# STM32L162ZET6 register map
File version: 1.0
Registers are 32-bit, access not given, reset 0x0 unless marked. A register's access mark holds for its fields unless they carry their own. Offsets are from the block's base; [hi:lo] are bit positions; {n}, {i} and the like mark numbered series.

## COMP
Base 0x40007C00
Same registers: COMP1 0x40007C00, COMP12_COMMON 0x40007C00, COMP2 0x40007C01
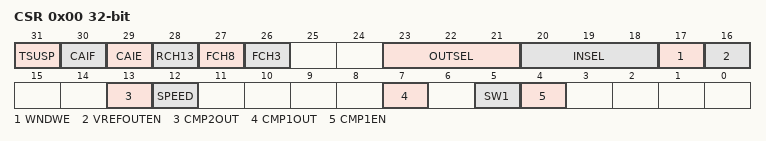
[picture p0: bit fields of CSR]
0x00 CSR
  [31] TSUSP, [30] CAIF, [29] CAIE, [28] RCH13, [27] FCH8, [26] FCH3, [23:21] OUTSEL, [20:18] INSEL, [17] WNDWE, [16] VREFOUTEN, [13] CMP2OUT, [12] SPEED, [7] CMP1OUT, [5] SW1, [4] CMP1EN

## RI
Base 0x40007C04
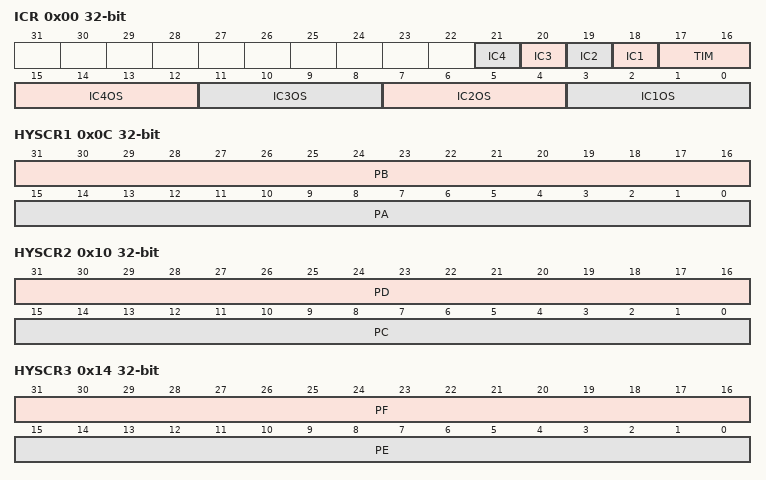
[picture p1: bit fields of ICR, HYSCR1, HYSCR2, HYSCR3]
0x00 ICR
  [n+17] IC{n} (n=1..4), [17:16] TIM, [4n-1:4n-4] IC{n}OS (n=1..4)
0x04 ASCR1
  [31] SCM, [26] VCOMP, [30:0] CH
0x08 ASCR2
  [n+14] CH{n}b (n=6..12), [n+16] CH{n}b (n=0..3), [28:4] GR6
0x0C HYSCR1
  [31:16] PB, [15:0] PA
0x10 HYSCR2
  [31:16] PD, [15:0] PC
0x14 HYSCR3
  [31:16] PF, [15:0] PE
0x18 HYSCR4
  [15:0] PG
0x1C ASMR1
  [15:0] PA
0x20 CMR1
  [15:0] PA
0x24 CICR1
  [15:0] PA
0x28 ASMR2
  [15:0] PB
0x2C CMR2
  [15:0] PB
0x30 CICR2
  [15:0] PB
0x34 ASMR3
  [15:0] PC
0x38 CMR3
  [15:0] PC
0x3C CICR3
  [15:0] PC
0x40 ASMR4
  [15:0] PF
0x44 CMR4
  [15:0] PF
0x48 CICR4
  [15:0] PF
0x4C ASMR5
  [15:0] PG
0x50 CMR5
  [15:0] PG
0x54 CICR5
  [15:0] PG

## OPAMP
Base 0x40007C5C
Same registers: OPAMP1 0x40007C5C, OPAMP2 0x40007C5D
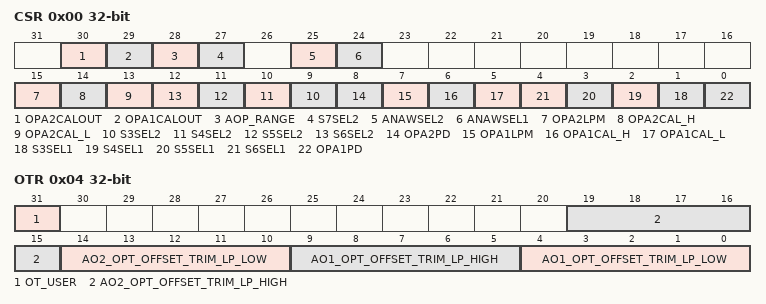
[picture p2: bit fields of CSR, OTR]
0x00 CSR
  [30] OPA2CALOUT, [29] OPA1CALOUT, [28] AOP_RANGE, [27] S7SEL2, [25] ANAWSEL2, [24] ANAWSEL1, [15] OPA2LPM, [14] OPA2CAL_H, [13] OPA2CAL_L, [n+6] S{n}SEL2 (n=3..6), [8] OPA2PD, [7] OPA1LPM, [6] OPA1CAL_H, [5] OPA1CAL_L, [n-2] S{n}SEL1 (n=3..6), [0] OPA1PD
0x04 OTR
  [31] OT_USER, [19:15] AO2_OPT_OFFSET_TRIM_LP_HIGH, [14:10] AO2_OPT_OFFSET_TRIM_LP_LOW, [9:5] AO1_OPT_OFFSET_TRIM_LP_HIGH, [4:0] AO1_OPT_OFFSET_TRIM_LP_LOW
0x08 LPOTR

## OPAMP12_COMMON
Base 0x40007C5C
Registers as OPAMP, without LPOTR.

## SYSCFG
Base 0x40010000
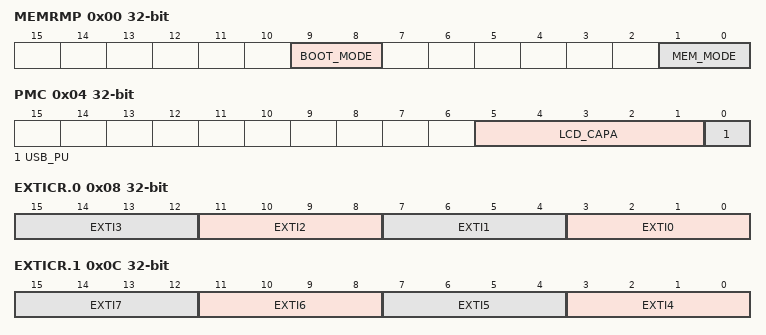
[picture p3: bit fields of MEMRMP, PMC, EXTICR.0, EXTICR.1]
0x00 MEMRMP
  [9:8] BOOT_MODE, [1:0] MEM_MODE
0x04 PMC
  [5:1] LCD_CAPA, [0] USB_PU
0x08 EXTICR.0
  [4n+3:4n] EXTI{n} (n=0..3)
0x0C EXTICR.1
  [4n-13:4n-16] EXTI{n} (n=4..7)
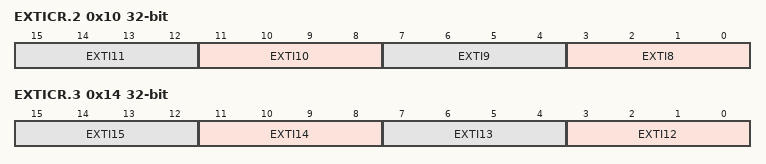
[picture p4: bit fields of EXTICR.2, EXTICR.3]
0x10 EXTICR.2
  [4n-29:4n-32] EXTI{n} (n=8..11)
0x14 EXTICR.3
  [4n-45:4n-48] EXTI{n} (n=12..15)

## EXTI
Base 0x40010400
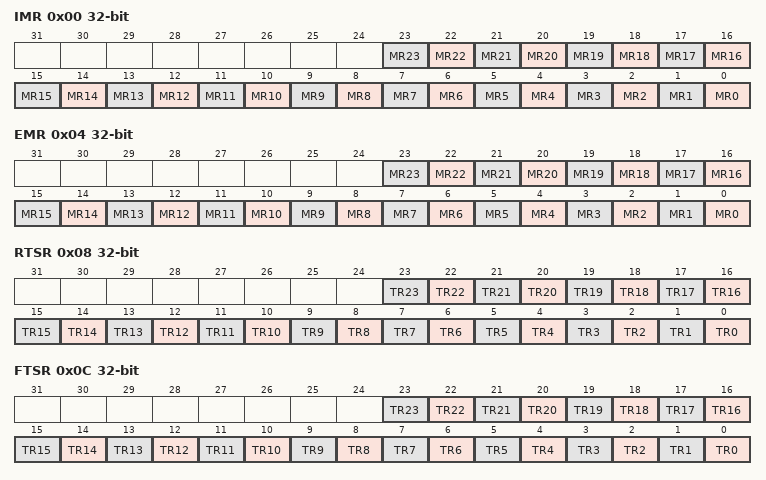
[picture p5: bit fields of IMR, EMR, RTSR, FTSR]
0x00 IMR
  [n] MR{n} (n=0..23)
0x04 EMR
  [n] MR{n} (n=0..23)
0x08 RTSR
  [n] TR{n} (n=0..23)
0x0C FTSR
  [n] TR{n} (n=0..23)
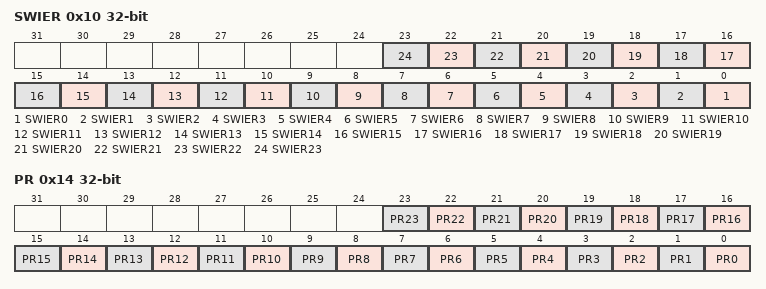
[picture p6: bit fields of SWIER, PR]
0x10 SWIER
  [n] SWIER{n} (n=0..23)
0x14 PR
  [n] PR{n} (n=0..23)

## ADC1
Base 0x40012400
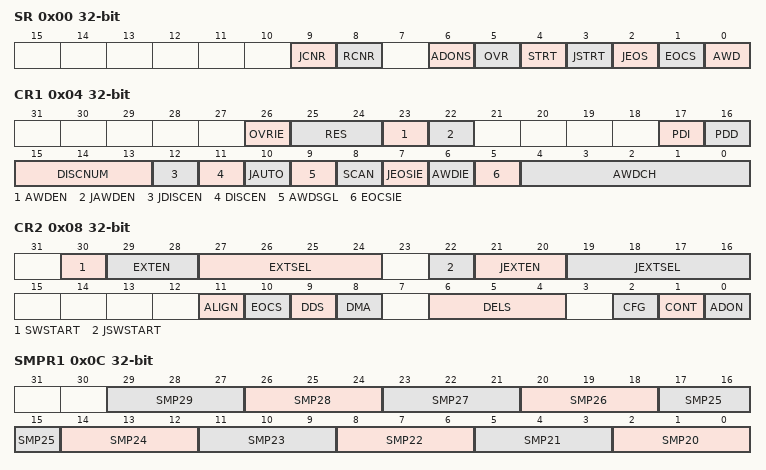
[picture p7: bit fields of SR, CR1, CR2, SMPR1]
0x00 SR
  [9] JCNR, [8] RCNR, [6] ADONS, [5] OVR, [4] STRT, [3] JSTRT, [2] JEOS, [1] EOCS, [0] AWD
0x04 CR1
  [26] OVRIE, [25:24] RES, [23] AWDEN, [22] JAWDEN, [17] PDI, [16] PDD, [15:13] DISCNUM, [12] JDISCEN, [11] DISCEN, [10] JAUTO, [9] AWDSGL, [8] SCAN, [7] JEOSIE, [6] AWDIE, [5] EOCSIE, [4:0] AWDCH
0x08 CR2
  [30] SWSTART, [29:28] EXTEN, [27:24] EXTSEL, [22] JSWSTART, [21:20] JEXTEN, [19:16] JEXTSEL, [11] ALIGN, [10] EOCS, [9] DDS, [8] DMA, [6:4] DELS, [2] CFG, [1] CONT, [0] ADON
0x0C SMPR1
  [3n-58:3n-60] SMP{n} (n=20..29)
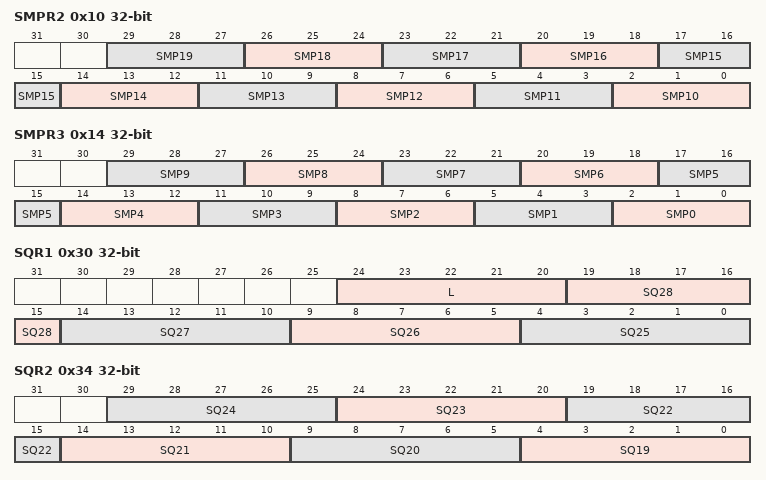
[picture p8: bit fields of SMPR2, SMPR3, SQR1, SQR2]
0x10 SMPR2
  [3n-28:3n-30] SMP{n} (n=10..19)
0x14 SMPR3
  [3n+2:3n] SMP{n} (n=0..9)
{0x14+4i} JOFR{i} (i=1..4)
  [11:0] JOFFSET{i}
0x28 HTR
  [11:0] HT
0x2C LTR
  [11:0] LT
0x30 SQR1
  [24:20] L, [5n-121:5n-125] SQ{n} (n=25..28)
0x34 SQR2
  [5n-91:5n-95] SQ{n} (n=19..24)
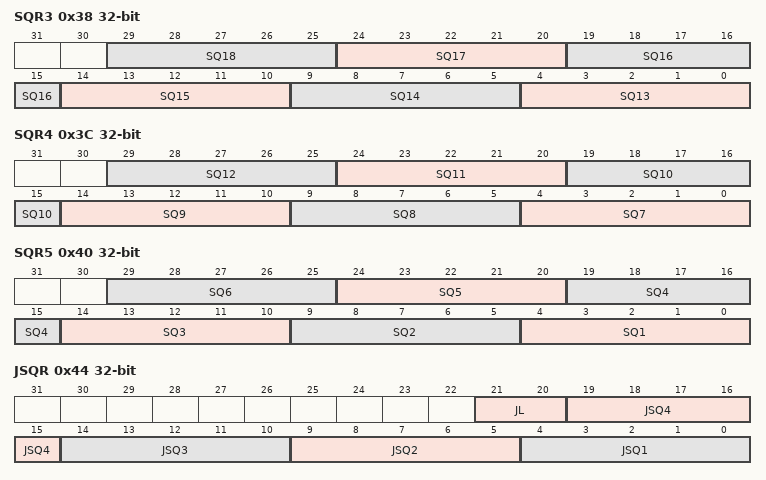
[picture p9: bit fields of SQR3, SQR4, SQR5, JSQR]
0x38 SQR3
  [5n-61:5n-65] SQ{n} (n=13..18)
0x3C SQR4
  [5n-31:5n-35] SQ{n} (n=7..12)
0x40 SQR5
  [5n-1:5n-5] SQ{n} (n=1..6)
0x44 JSQR
  [21:20] JL, [5n-1:5n-5] JSQ{n} (n=1..4)
{0x44+4i} JDR{i} (i=1..4)
  [15:0] JDATA
0x58 DR
  [15:0] DATA
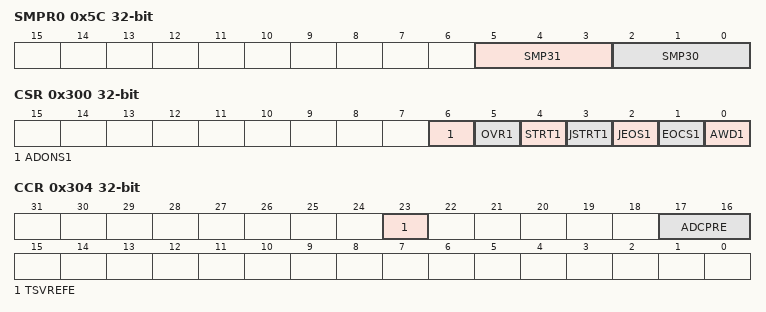
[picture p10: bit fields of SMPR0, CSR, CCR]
0x5C SMPR0
  [5:3] SMP31, [2:0] SMP30
0x300 CSR
  [6] ADONS1, [5] OVR1, [4] STRT1, [3] JSTRT1, [2] JEOS1, [1] EOCS1, [0] AWD1
0x304 CCR
  [23] TSVREFE, [17:16] ADCPRE

## GPIOA
Base 0x40020000
Same registers: GPIOB 0x40020400, GPIOC 0x40020800, GPIOD 0x40020C00, GPIOE 0x40021000, GPIOH 0x40021400, GPIOF 0x40021800, GPIOG 0x40021C00
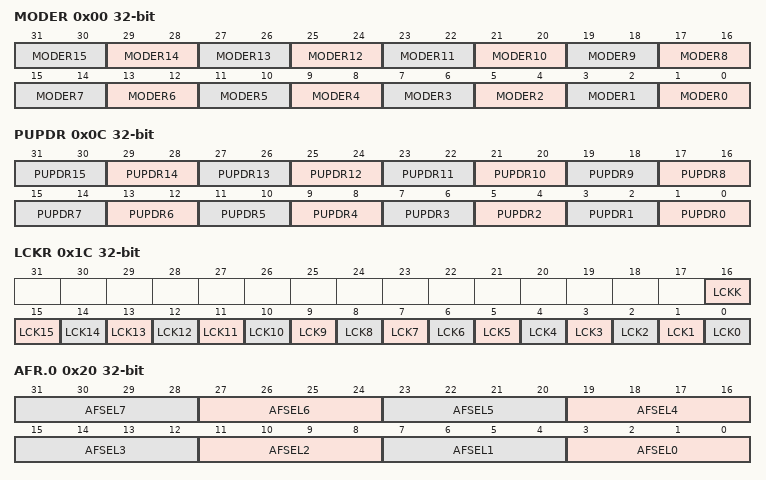
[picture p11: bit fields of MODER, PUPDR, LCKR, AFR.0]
0x00 MODER
  [2n+1:2n] MODER{n} (n=0..15)
0x04 OTYPER
0x08 OSPEEDR
0x0C PUPDR
  [2n+1:2n] PUPDR{n} (n=0..15)
0x10 IDR
0x14 ODR
0x18 BSRR
0x1C LCKR
  [16] LCKK, [n] LCK{n} (n=0..15)
0x20 AFR.0
  [4n+3:4n] AFSEL{n} (n=0..7)
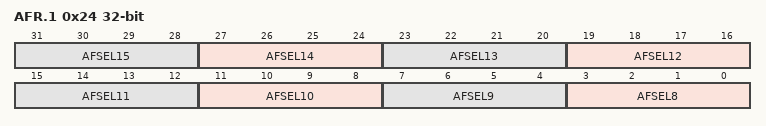
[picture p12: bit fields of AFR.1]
0x24 AFR.1
  [4n-29:4n-32] AFSEL{n} (n=8..15)
0x28 BRR
